VERSION ""

NS_ :

BS_:

BU_: DBG VCU
VAL_TABLE_ WhySpeedLimit 30014 "DCDC Temp fault" 30013 "Drive clutch stuck" 30012 "PTO clutch stuck" 30011 "Transmission pressure sensor OOR" 30010 "Clutch Brake interlock" 30009 "Hydraulic over temp" 30008 "Steering issue" 30007 "Brake Pedal Position Sensor OOR" 30006 "Right Brake Position Sensor OOR" 30005 "Left Brake Position Sensor OOR" 30004 "Right wheel speed sensor OOR" 30003 "Left wheel speed sensor OOR" 30002 "Brakes requested" 30001 "Zero speed limit from the roof" 30000 "Good" ;
VAL_TABLE_ Steering_Faults 20826 "Right Pressure Out of Range" 20825 "Left Pressure Out of Range" 20824 "TFD Loss of Comm" 20823 "Sensor Not Calibrated" 20822 "Valve Stuck Open towards Right" 20821 "Ecotron Loss of Comm" 20820 "LH Red Sensor Out of Calibration" 20819 "RH Red sensor Out of Calibration" 20818 "Steering Loss of Comm" 20817 "Left Red Sensor Open Cicruit" 20816 "Rght Snsor Failed Crosscheck" 20815 "Right Redundant Sensor OC" 20814 "RH Red Sensor Short to Pwr" 20813 "Valve Stuck Closed" 20812 "Left Sensor Failed Crosscheck" 20811 "Left Red Sensor Short to Pwr" 20810 "Left Valve Stuck Open" 20809 "Right Line Pressure Too High" 20808 "Left Line Pressure Too High" 20807 "LH Primary Out of Calibration" 20806 "RH Primary Out of Calibration" 20805 "Primary Primary Xcheck Error" 20804 "LH Sensor Primary Short to pwr" 20803 "RH Sensor Primary short to pwr" 20802 "Left Sensor Primary OC" 20801 "Right Sensor Primary OC" 20800 "No Faults" 0 "No Faults" ;
VAL_TABLE_ VT_Gearbox_Subsystem 0 "No Fault" 20609 "Broken roll pin or clutch slip" 20608 "Range shifting stuck" 20607 "Gear shifting stuck" 20606 "Range sensor out of range" 20605 "Gear sensor out of range" 20604 "Shift Dial fault" 20603 "Shift Dial LoC" 20602 "Left Ecotron LoC" 20601 "Right Ecotron LoC" 20600 "No Fault" ;
VAL_TABLE_ ChargerPP 2 "Charger Connected" 1 "Charger Detected" 0 "Not connected" ;
VAL_TABLE_ Charger_PP 2 "Charger Connected" 1 "Charger Detected" 0 "Charger Not Connected" ;
VAL_TABLE_ General_Flt 20066 "Front Aux Power Flt" 20065 "Front PCB Flt" 20064 "Rear Aux Power Flt" 20063 "Rear PCB Flt" 20062 "Rear Light Flt" 20061 "Front Light Flt" 20060 "Spare Power Flt" 20059 "Left Light Flt" 20058 "Right Light Flt" 20057 "AV Power Flt" 20056 "Wifi power Flt" 20055 "Front Fans Flt" 20054 "PE fan Flt" 20053 "Oil Fan Flt" 20052 "PE Pump Flt" 20051 "12V outlet Flt" 20050 "Front Light Strip Flt" 20049 "Ix_bed Ch7 Flt" 20048 "Charger Relay Flt" 20047 "Trailer Brake Light Flt" 20046 "Ix_bed Ch4 Flt" 20045 "High beam Flt" 20044 "Low Beam Flt" 20043 "Running Light Flt" 20042 "Relay14_ACDB Power" 20041 "Relay13_Front Sensor" 20040 "Relay12_BattPower" 20039 "Relay11_HV Ign" 20038 "Relay10_TFD Ign" 20037 "Relay9_TTC580 Ign" 20036 "Relay8_TTC580 Power" 20035 "Relay7_ Pump Ign" 20034 "Relay6_HMI Ign" 20033 "Relay5_EHI Ign" 20032 "Relay4_Right Turn Signal" 20031 "Relay3_mRFRM Ign" 20030 "Relay2_Left Turn Signal " 20029 "Relay1_Autonomy Cams" 20028 "Fuse28_TTC580 Power" 20027 "Fuse27_Ecotrons2" 20026 "Fuse26_ACDB Power" 20025 "Fuse25_Front Sensor" 20024 "Fuse24_BMS power" 20023 "Fuse23_HV Ign" 20022 "Fuse22_mRFRFM Power" 20021 "Fuse21_ Ecotrons1" 20020 "Fuse20_Vmax Power" 20019 "Fuse19_ OTA TTC580" 20018 "Fuse18_TFD" 20017 "Fuse17_TTC580 Ubatt" 20016 "Fuse16_TractorPump Ign" 20015 "Fuse15_ TTC580 Ign" 20014 "Fuse14_SevconPower2" 20013 "Fuse13_SevconPower1" 20012 "Fuse12_ SIMPL Power" 20011 "Fuse11_MTA Power" 20010 "Fuse10_Steering Valve" 20009 "Fuse9_ HMI Power" 20008 "Fuse8_Right Turn Signal" 20007 "Fuse7_Left Turn Signal" 20006 "Fuse6_empty" 20005 "Fuse5_ISOBus Power" 20004 "Fuse4_EstopCharger" 20003 "Fuse3_empty" 20002 "Fuse2_VmaxHVIL" 20001 "Fuse1_Autonomy Cams" 0 "No Fault" ;
VAL_TABLE_ Battery_Subsystem 24 "HV battery Low" 23 "12 Battery Low" 22 "Tractor HVIL" 21 "BMS HVIL" 20 "Lower BMS Severe Fault" 19 "Lower String High CellV" 18 "Lower String Over Voltage" 17 "Lower String Low CellV" 16 "Lower String Low Voltage" 15 "Upper BMS Severe Fault" 14 "Upper String High CellV" 13 "Upper String Over Voltage" 12 "Upper String Low CellV" 11 "Upper String low Voltage" 10 "Pack imbl_ Upper Active" 9 "Pack imbl_ Lower Active" 8 "SOC Critically Low" 7 "Low SOC" 6 "Lower String Down" 5 "Upper String Down" 4 "Voltage Imbalance" 3 "Both BMS LOC" 2 "Lower String LOC" 1 "Upper String LOC" 0 "No Fault" ;
VAL_TABLE_ Hydraulics_Flt 37 "Work Pump Pos OOR" 36 "Drive Clutch Pressure OOR" 35 "PTO Clutch Pressure OOR" 34 "Trans Acc Pressure OOR" 33 "SteerBrk Acc Pressure OOR" 32 "Suction Line Pressure OOR" 31 "Tractor Pump Pressure OOR" 30 "Work Pump Pressure OOR" 29 "Right Brake Pressure OOR" 28 "Left Brake Pressure OOR" 27 "Tractor Pump OverLoaded" 26 "RH Brake Out Of Calibration" 25 "LH Brake Out Of Calibration" 24 "RH Brake SetValve OpenCircuit" 23 "RH Brake RelValve OpenCircuit" 22 "LH Brake SetValve OpenCircuit" 21 "LH Brake RelValve OpenCircuit" 20 "RH Brake Under Engagement" 19 "LH Brake Under Engagement" 18 "RH Brake Over Engagement" 17 "LH Brake Over Engagement" 16 "PTO Engagement Interlock" 15 "PTO Clutch Valve OpenCircuit" 14 "Lube Valve OpenCircuit" 13 "Drive Clutch Valve OpenCircuit" 12 "Lube Valve Timeout" 11 "Gear mismatch clutch disengaged" 10 "Clutch Pressure Low" 9 "Aux ON/OFFvalve OpenCircuit" 8 "WorkPumpOverloaded/Air" 7 "PTO Clutch Pressure Low" 6 "TransFlowValve OpenCircuit" 5 "Trans Manifold Pressure High" 4 "Trans Manifold Pressure Low" 3 "SteerBrake Valve OpenCircuit" 2 "SteerBrake Acc Press High" 1 "SteerBrake Acc Press Low" 0 "No Fault" ;
VAL_TABLE_ Charging_Flt 32 "Chargers Disabled" 31 "DCAC_3 Flt" 30 "DCAC_2 Flt" 29 "DCAC_1 Flt" 28 "DCDC_3 Irregular Voltage" 27 "DCDC_2 Irregular Voltage" 26 "DCDC_1 Irregular Voltage" 25 "Chg_3 OBC Flt" 24 "Chg_2 OBC Flt" 23 "Chg_1 OBC Flt" 22 "DCDC_3 OverTemp" 21 "DCDC_2 OverTemp" 20 "DCDC_1 OverTemp" 19 "Chg_3 OverTemp " 18 "Chg_2 OverTemp" 17 "Chg_1 OverTemp" 16 "DCDC_3 Flt" 15 "DCDC_2 Flt" 14 "DCDC_1 Flt" 13 "ACDB eFuse8 OverCurrent" 12 "ACDB eFuse6 OverCurrent" 11 "ACDB eFuse3 OverCurrent" 10 "ACDB eFuse1 OverCurrent" 9 "ACDB Conv. Error" 8 "ACDB SIMPL Error" 7 "ACDB EVSE Error" 6 "ACDB 3Ph Error" 5 "ACDB 1Ph Error" 4 "ACDB OverTemp" 3 "ACDB disabled" 2 "Charger Improper Connection" 1 "Charger LOC" 0 "No Fault" ;
VAL_TABLE_ Thermal_Flt 5 "Hyd Over Temp Protection" 4 "Hyd Over Temp Warning" 3 "Cooling Pump Disconnected" 2 "Air in cooling system" 1 "Cooling Pump OverCurrent" 0 "No Fault" ;
VAL_TABLE_ Traction_Flt 23 "Inverter LOC" 22 "Regen Limited" 21 "Regen Disabled" 20 "Clutch Interlock" 19 "Motor Over loaded" 18 "bStart Check Fail" 17 "Disengage by Accel." 16 "Min Cell Voltage Low" 15 "DC Link Voltage Low" 14 "Pack Voltage Low" 13 "Speed Input Error" 12 "Motor Torque Limit" 11 "Insufficient Torque Applied" 10 "Hydraulic Oil Over Temp" 9 "Inverter Over Temperature" 8 "Inverter Fault OFF" 7 "Control Word Check Error" 6 "Hand Throttle Error" 5 "Hand Throttle Ch2 OOR" 4 "Hand Throttle Ch1 OOR" 3 "Foot Throttle Error" 2 "Foot Throttle Ch2 OOR" 1 "Foot Throttle Ch1 OOR" 0 "No Fault" ;
VAL_TABLE_ Shift_Position_Error 0 "Not In Any Target" ;
VAL_TABLE_ STATE_CONTACTORS 2 "CLOSED" 1 "PRECHARGE IN PROCESS" 0 "OPEN" ;
VAL_TABLE_ OVERRIDE_BRAKE_LIGHT 3 "FUNCTION NOT AVAILABLE" 2 "ENABLE OVERRIDE TO ON" 1 "ENABLE OVERRIDE TO OFF" 0 "DISABLE OVERRIDE" ;
VAL_TABLE_ STATE_SHIFT 2 "REVERSE" 1 "FORWARD" 0 "NEUTRAL/PARK" ;
VAL_TABLE_ STATE_GEAR_POSITION 12 "POSITION 12" 11 "POSITION 11" 10 "POSITION 10" 9 "POSITION 09" 8 "POSITION 08" 7 "POSITION 07" 6 "POSITION 06" 5 "POSITION 05" 4 "POSITION 04" 3 "POSITION 03" 2 "POSITION 02" 1 "POSITION 01" 0 "NEUTRAL" ;
VAL_TABLE_ STATE_HEAD_LIGHT 3 "HIGH_BEAM" 2 "LOW_BEAM" 1 "RUNNING_LIGHT" 0 "OFF" ;
VAL_TABLE_ STATE_TURN_SIGNAL 3 "HAZARD" 2 "RIGHT" 1 "LEFT" 0 "OFF" ;
VAL_TABLE_ State 7 "Reserved" 6 "Reserved" 5 "Float" 4 "Turn Off" 3 "Consider Turn Off" 2 "Tracking Active" 1 "Tracking Desired" 0 "Initialization" ;

BO_ 3221225472 VECTOR__INDEPENDENT_SIG_MSG: 0 Vector__XXX
 SG_ VehicleSpeed_kmoh : 0|8@1- (1,0) [0|0] "" Vector__XXX
 SG_ VCU_CtrlTrePt_EstimateMassFromFo : 0|12@1- (1,0) [-2048|2047] "kg" Vector__XXX
 SG_ VCU_CtrlTrePt_EndAHeight_Right : 0|8@1+ (0.01,0) [0|2.55] "m" Vector__XXX
 SG_ VCU_CtrlTrePt_EndAHeight_Left : 0|8@1+ (0.01,0) [0|2.55] "m" Vector__XXX
 SG_ VCU_CtrlTrePt_CylinderPosition_R : 0|8@1+ (0.4,0) [0|102] "%" Vector__XXX
 SG_ VCU_CtrlTrePt_CylinderPosition_L : 0|8@1+ (0.4,0) [0|102] "%" Vector__XXX
 SG_ VCU_CtrlTrePt_State_Right : 0|3@1+ (1,0) [0|7] "" Vector__XXX
 SG_ VCU_CtrlTrePt_State_Left : 0|3@1+ (1,0) [0|7] "" Vector__XXX
 SG_ VCU_CtrlTrePt_EnPressurePID_Righ : 0|1@1+ (1,0) [0|1] "" Vector__XXX
 SG_ VCU_CtrlTrePt_EnPressurePID_Left : 0|1@1+ (1,0) [0|1] "" Vector__XXX
 SG_ VCU_CtrlTrePt_Force_Right_OnGrou : 0|12@1- (0.01,0) [-20.48|20.47] "kN" Vector__XXX
 SG_ VCU_CtrlTrePt_Force_Right_Error : 0|14@1- (0.01,0) [-81.92|81.91] "kN" Vector__XXX
 SG_ VCU_CtrlTrePt_Force_Right_EquivM : 0|12@1- (0.01,0) [-20.48|20.47] "kN" Vector__XXX
 SG_ VCU_CtrlTrePt_Force_Right_Actual : 0|14@1- (0.01,0) [-81.92|81.91] "kN" Vector__XXX
 SG_ VCU_CtrlTrePt_Force_Right_Acc : 0|12@1- (0.01,0) [-20.48|20.47] "kN" Vector__XXX
 SG_ VCU_CtrlTrePt_Force_Left_OnGroun : 0|12@1- (0.01,0) [-20.48|20.47] "kN" Vector__XXX
 SG_ VCU_CtrlTrePt_Force_Left_Error : 0|14@1- (0.01,0) [-81.92|81.91] "kN" Vector__XXX
 SG_ VCU_CtrlTrePt_Force_Left_Actual : 0|14@1- (0.01,0) [-81.92|81.91] "kN" Vector__XXX
 SG_ VCU_CtrlTrePt_Force_Left_Acc : 0|12@1- (0.01,0) [-20.48|20.47] "kN" Vector__XXX
 SG_ VCU_CtrlTrePt_Force_Left_EquivMa : 0|12@1- (0.01,0) [-20.48|20.47] "kN" Vector__XXX
 SG_ power_hydraulic : 0|16@1+ (1,0) [0|65535] "W" Vector__XXX
 SG_ power_DCDC : 0|12@1+ (1,0) [0|4095] "W" Vector__XXX
 SG_ three_point_depth_position_senso : 0|14@1+ (1,0) [0|16383] "mV" Vector__XXX
 SG_ do3_right_three_point_up_valve_d : 0|16@1+ (0.00152590218966964,0) [0|100] "%" Vector__XXX
 SG_ do3_right_three_point_down_valve : 0|16@1+ (0.00152590218966964,0) [0|100] "%" Vector__XXX
 SG_ three_point_depth_position__0000 : 0|14@1+ (1,0) [0|16383] "mV" Vector__XXX
 SG_ do3_left_three_point_down_valve_ : 0|16@1+ (0.00152590218966964,0) [0|100] "%" Vector__XXX
 SG_ do3_left_three_point_up_valve_du : 0|16@1+ (0.00152590218966964,0) [0|100] "%" Vector__XXX
 SG_ range_control_execute : 0|1@1+ (1,0) [0|1] "" Vector__XXX
 SG_ range_control_done : 0|1@1+ (1,0) [0|1] "" Vector__XXX
 SG_ range_control_busy : 0|1@1+ (1,0) [0|1] "" Vector__XXX
 SG_ range_control_abort : 0|1@1+ (1,0) [0|1] "" Vector__XXX
 SG_ range_target_position_voltage : 0|13@1+ (1,0) [0|8191] "mV" Vector__XXX
 SG_ range_target_position_logical : 0|4@1+ (1,0) [0|15] "" Vector__XXX
 SG_ range_feedback_position_voltage : 0|13@1+ (1,0) [0|8191] "mV" Vector__XXX
 SG_ range_feedback_position_logical : 0|4@1+ (1,0) [0|15] "" Vector__XXX
 SG_ gear_control_abort : 0|1@1+ (1,0) [0|1] "" Vector__XXX
 SG_ gear_control_busy : 0|1@1+ (1,0) [0|1] "" Vector__XXX
 SG_ gear_control_done : 0|1@1+ (1,0) [0|1] "" Vector__XXX
 SG_ gear_control_execute : 0|1@1+ (1,0) [0|1] "" Vector__XXX
 SG_ gear_feedback_position_logical : 0|4@1+ (1,0) [0|15] "" Vector__XXX
 SG_ gear_target_position_logical : 0|4@1+ (1,0) [0|15] "" Vector__XXX
 SG_ gear_feedback_position_voltage : 0|13@1+ (1,0) [0|8191] "mV" Vector__XXX
 SG_ gear_target_position_voltage : 0|13@1+ (1,0) [0|8191] "mV" Vector__XXX
 SG_ right_wheel_speed_sensor_motion_ : 0|1@1+ (1,0) [0|1] "" Vector__XXX
 SG_ right_wheel_speed_sensor_calcula : 0|12@1+ (0.001,0) [0|4.095] "" Vector__XXX
 SG_ right_wheel_speed_sensor_pulse_w : 0|24@1+ (1,0) [0|16777215] "us" Vector__XXX
 SG_ right_wheel_speed_sensor_freq_ra : 0|16@1+ (1,0) [0|65535] "mHz" Vector__XXX
 SG_ right_wheel_speed_sensor_error : 0|8@1+ (1,0) [0|255] "" Vector__XXX
 SG_ RightBrkSpeed_Pcnt : 0|8@1+ (1,0) [0|255] "%" Vector__XXX
 SG_ LeftBrkSpeed_Pcnt : 0|8@1+ (1,0) [0|255] "%" Vector__XXX
 SG_ right_wheel_speed_raw : 0|8@1+ (1,0) [0|255] "rpm" Vector__XXX
 SG_ left_wheel_speed_raw : 0|8@1+ (1,0) [0|65535] "rpm" Vector__XXX
 SG_ right_whee_speed : 0|8@1+ (1,0) [0|65535] "rpm" Vector__XXX
 SG_ left_whee_speed : 0|8@1+ (1,0) [0|65535] "rpm" Vector__XXX
 SG_ left_wheel_speed_sensor_motion_d : 0|1@1+ (1,0) [0|1] "" Vector__XXX
 SG_ left_wheel_speed_sensor_calculat : 0|12@1+ (0.001,0) [0|4.095] "" Vector__XXX
 SG_ left_wheel_speed_sensor_error : 0|8@1+ (1,0) [0|255] "" Vector__XXX
 SG_ left_wheel_speed_sensor_pulse_wi : 0|24@1+ (1,0) [0|16777215] "us" Vector__XXX
 SG_ left_wheel_speed_sensor_freq_raw : 0|16@1+ (1,0) [0|65535] "mHz" Vector__XXX
 SG_ brake_pedal_switch : 0|1@1+ (1,0) [0|1] "" Vector__XXX
 SG_ three_point_depth_position__0001 : 0|12@1+ (0.025,0) [0|102.375] "%" Vector__XXX
 SG_ do3_auxiliary_b_front_a_pressure : 0|12@1+ (1,0) [0|4095] "psi" Vector__XXX
 SG_ do3_auxiliary_b_front_b_pressure : 0|12@1+ (1,0) [0|4095] "psi" Vector__XXX
 SG_ do3_auxiliary_b_rear_a_pressure : 0|12@1+ (1,0) [0|4095] "psi" Vector__XXX
 SG_ do3_auxiliary_b_rear_b_pressure : 0|12@1+ (1,0) [0|4095] "psi" Vector__XXX
 SG_ three_point_depth_position__0002 : 0|12@1+ (0.025,0) [0|102.375] "%" Vector__XXX
 SG_ do3_auxiliary_a_front_a_pressure : 0|12@1+ (1,0) [0|4095] "psi" Vector__XXX
 SG_ do3_auxiliary_a_front_b_pressure : 0|12@1+ (1,0) [0|4095] "psi" Vector__XXX
 SG_ do3_auxiliary_a_rear_a_pressure : 0|12@1+ (1,0) [0|4095] "psi" Vector__XXX
 SG_ do3_auxiliary_a_rear_b_pressure : 0|12@1+ (1,0) [0|4095] "psi" Vector__XXX
 SG_ do3_front_axle_forward_pressure : 0|12@1+ (1,0) [0|4095] "psi" Vector__XXX
 SG_ do3_front_axle_reverse_pressure : 0|12@1+ (1,0) [0|4095] "psi" Vector__XXX
 SG_ do3_implement_pressure : 0|12@1+ (1,0) [0|4095] "psi" Vector__XXX
 SG_ trans_manifold_forward_pressure : 0|12@1+ (1,0) [0|4095] "psi" Vector__XXX
 SG_ trans_manifold_reverse_pressure : 0|12@1+ (1,0) [0|4095] "psi" Vector__XXX
 SG_ trans_manifold_accumulator_press : 0|12@1+ (1,0) [0|4095] "psi" Vector__XXX
 SG_ trans_manifold_system_pressure : 0|12@1+ (1,0) [0|4095] "psi" Vector__XXX
 SG_ brake_manifold_steer_brake_accum : 0|12@1+ (1,0) [0|4095] "psi" Vector__XXX
 SG_ brake_manifold_right_hand_brake_ : 0|12@1+ (1,0) [0|4095] "psi" Vector__XXX
 SG_ brake_manifold_left_hand_brake_p : 0|12@1+ (1,0) [0|4095] "psi" Vector__XXX
 SG_ pump_power_watts : 0|16@1+ (1,0) [0|65535] "W" Vector__XXX
 SG_ pump_flow_rate_lpm : 0|16@1+ (0.001,0) [0|40] "lpm" Vector__XXX
 SG_ stock_pto_engage_valve : 0|1@1+ (1,0) [0|1] "T/F" Vector__XXX
 SG_ trans_manifold_lubrication_valve : 0|1@1+ (1,0) [0|1] "T/F" Vector__XXX
 SG_ priority_on_off_valve : 0|16@1+ (0.00152590218966964,0) [0|100] "%" Vector__XXX
 SG_ trans_manifold_reverse_valve : 0|16@1+ (0.00152590218966964,0) [0|100] "%" Vector__XXX
 SG_ trans_manifold_forward_valve : 0|16@1+ (0.00152590218966964,0) [0|100] "%" Vector__XXX
 SG_ brake_manifold_right_hand_b_0000 : 0|16@1+ (0.00152590218966964,0) [0|100] "%" Vector__XXX
 SG_ brake_manifold_left_hand_brake_s : 0|16@1+ (0.00152590218966964,0) [0|100] "%" Vector__XXX
 SG_ FWD_RPM : 0|16@1- (0.1,0) [-3276.8|3276.7] "" Vector__XXX
 SG_ energy_hydraulic : 0|12@1+ (3,0) [0|12285] "Wh" Vector__XXX
 SG_ energy_DCDC : 0|12@1+ (3,0) [0|12285] "Wh" Vector__XXX
 SG_ energy_battery : 0|16@1- (4,0) [-131072|131068] "Wh" Vector__XXX
 SG_ energy_mechanical : 0|16@1- (4,0) [-131072|131068] "Wh" Vector__XXX
 SG_ FWDbraking_SM_diag : 0|5@1- (0.5,0) [-8|7.5] "" Vector__XXX
 SG_ ShiftState : 0|5@1+ (1,0) [0|31] "" Vector__XXX
 SG_ SM1_3Pt_Toplink_Angle_mV : 0|13@1+ (1,0) [0|8191] "" Vector__XXX
 SG_ SM1_3Pt_Toplink_Angle_pct : 0|6@1- (1.6,0) [-51.2|49.6] "" Vector__XXX
 SG_ SM1_3Pt_RH_Angle_pct : 0|6@1+ (1.6,0) [0|0] "" Vector__XXX
 SG_ SM1_3Pt_RH_Angle_mV : 0|13@1+ (1,0) [0|8191] "" Vector__XXX
 SG_ SM1_3Pt_LH_Angle_pct : 0|6@1+ (1.6,0) [0|100.8] "" Vector__XXX
 SG_ SM1_3Pt_LH_Angle_mV : 0|13@1+ (1,0) [0|8191] "" Vector__XXX

BO_ 1901 VCU_FaultCodes: 8 Vector__XXX
 SG_ whyDisabled m3 : 24|8@1+ (1,30300) [30300|30555] "" Vector__XXX
 SG_ WhySpeedLimit m1 : 56|8@1+ (1,30000) [30000|30255] "" Vector__XXX
 SG_ Accessories_Subsystem m3 : 8|16@1+ (1,0) [0|255] "" Vector__XXX
 SG_ FirstFault m0 : 56|8@1+ (1,0) [0|255] "" Vector__XXX
 SG_ IMPL_Subsystem m2 : 40|16@1+ (1,0) [0|255] "" Vector__XXX
 SG_ Steering_Subsystem m2 : 24|16@1+ (1,0) [0|255] "" Vector__XXX
 SG_ Gearbox_Subsystem m2 : 8|16@1+ (1,0) [0|255] "" Vector__XXX
 SG_ General_Subsytem m1 : 40|16@1+ (1,0) [0|255] "" Vector__XXX
 SG_ Battery_Subsystem m1 : 24|16@1+ (1,0) [0|255] "" Vector__XXX
 SG_ Hydraulic_Subsystem m1 : 8|16@1+ (1,0) [0|65535] "" Vector__XXX
 SG_ Charging_Subsystem m0 : 40|16@1+ (1,0) [0|32767] "" Vector__XXX
 SG_ Fault_Code_mux M : 0|8@1+ (1,0) [0|255] "" Vector__XXX
 SG_ Thermal_Subsystem m0 : 24|16@1+ (1,0) [0|65535] "" Vector__XXX
 SG_ Traction_Subsystem m0 : 8|16@1+ (1,0) [0|65535] "" Vector__XXX

BO_ 1300 VCU_Geartrain: 8 Vector__XXX
 SG_ SunGearRPM m4 : 34|16@1- (0.05,0) [-1638.4|1638.35] "" Vector__XXX
 SG_ ShiftFeedback m1 : 52|4@1+ (1,0) [0|15] "" Vector__XXX
 SG_ Charger_PP m2 : 54|2@1+ (1,0) [0|3] "" Vector__XXX
 SG_ Power_Motor_kW_Output m1 : 8|8@1- (1,0) [-128|127] "kW" Vector__XXX
 SG_ Power_Wheel_kW m2 : 0|10@1- (0.1,0) [-51.2|51.1] "kW" Vector__XXX
 SG_ Power_PumpMech_kW m2 : 56|4@1+ (0.2,0) [0|3] "kW" Vector__XXX
 SG_ Power_PumpHyd_kW m2 : 10|8@1+ (0.1,0) [0|25.5] "kW" Vector__XXX
 SG_ Power_PTO_kW m2 : 26|10@1- (0.1,0) [-51.2|51.1] "kW" Vector__XXX
 SG_ Power_Motor_kW_input m2 : 36|8@1- (1,0) [-128|127] "kW" Vector__XXX
 SG_ Power_Drivetrain_kW m2 : 44|10@1- (0.1,20) [-31.2|71.1] "kW" Vector__XXX
 SG_ Power_Battery_kW m2 : 18|8@1- (1,0) [-128|127] "kW" Vector__XXX
 SG_ kWh_per_min m3 : 0|5@1+ (1,0) [0|31] "" Vector__XXX
 SG_ SOC_Rate m3 : 5|4@1+ (1,0) [0|15] "" Vector__XXX
 SG_ TTE m3 : 9|10@1+ (1,0) [0|1023] "" Vector__XXX
 SG_ GoodStringState m3 : 19|3@1+ (1,0) [0|7] "" Vector__XXX
 SG_ Update m3 : 22|1@1+ (1,0) [0|1] "" Vector__XXX
 SG_ T_Init m4 : 0|10@1+ (1,0) [0|1023] "" Vector__XXX
 SG_ SOC_Init m4 : 10|7@1+ (1,0) [0|127] "" Vector__XXX
 SG_ Prev_T m4 : 17|10@1+ (1,0) [0|1023] "" Vector__XXX
 SG_ Prev_SOC m4 : 27|7@1+ (1,0) [0|127] "" Vector__XXX
 SG_ Plug m3 : 23|1@1+ (1,0) [0|1] "" Vector__XXX
 SG_ Clock m3 : 24|10@1+ (1,0) [0|1023] "" Vector__XXX
 SG_ Current_SOC m3 : 34|7@1+ (1,0) [0|127] "" Vector__XXX
 SG_ u8_State m3 : 41|4@1+ (1,0) [0|15] "" Vector__XXX
 SG_ FWDbraking_SM_diag m3 : 50|5@1- (0.5,0) [-8|7.5] "" Vector__XXX
 SG_ FWD_slip_pcnt m1 : 0|8@1- (1,0) [-128|127] "%" Vector__XXX
 SG_ FWD_Target_RPM m1 : 32|16@1- (0.1,0) [-3276.8|3276.7] "" Vector__XXX
 SG_ FWD_RPM_KF m1 : 16|16@1- (0.1,0) [-3276.8|3276.7] "" Vector__XXX
 SG_ Geartrain_MUX M : 60|4@1+ (1,0) [0|15] "" Vector__XXX
 SG_ ShiftState m3 : 45|5@1+ (1,0) [0|31] "" Vector__XXX
 SG_ TargetRightwheelSpeed m0 : 52|8@1+ (1,0) [0|255] "RPM" Vector__XXX
 SG_ TargetRightBrake_Pcnt m0 : 45|7@1+ (1,0) [0|127] "" Vector__XXX
 SG_ TargetLeftwheelSpeed m0 : 37|8@1+ (1,0) [0|255] "RPM" Vector__XXX
 SG_ TargetLeftBrake_Pcnt m0 : 30|7@1+ (1,0) [0|127] "" Vector__XXX
 SG_ RightBrake_Pcnt m0 : 23|7@1+ (1,0) [0|127] "" Vector__XXX
 SG_ LeftBrake_Pcnt m0 : 16|7@1+ (1,0) [0|127] "" Vector__XXX
 SG_ RangeTargetPos m0 : 12|4@1+ (1,0) [0|15] "" Vector__XXX
 SG_ RangeFBKPos m0 : 8|4@1+ (1,0) [0|15] "" Vector__XXX
 SG_ GearTargetPos m0 : 4|4@1+ (1,0) [0|15] "" Vector__XXX
 SG_ GearFBKPos m0 : 0|4@1+ (1,0) [0|15] "" Vector__XXX

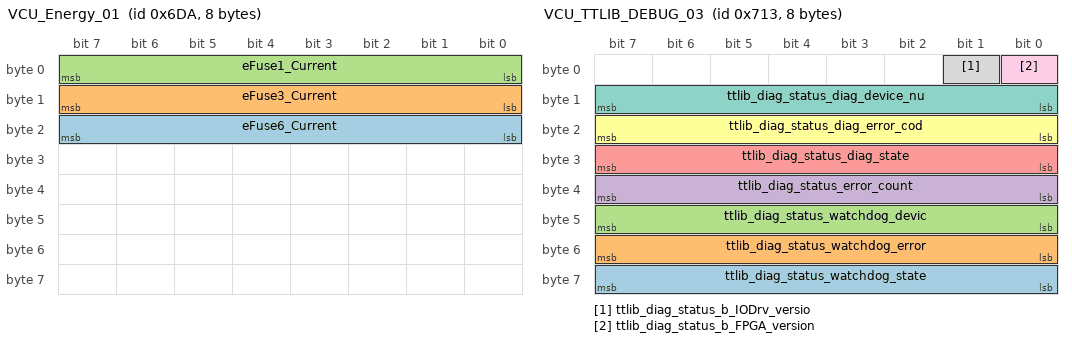
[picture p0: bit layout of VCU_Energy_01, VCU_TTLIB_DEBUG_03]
BO_ 1754 VCU_Energy_01: 8 VCU
 SG_ eFuse6_Current : 16|8@1+ (0.2,0) [0|51] "A" Vector__XXX
 SG_ eFuse3_Current : 8|8@1+ (0.2,0) [0|51] "A" Vector__XXX
 SG_ eFuse1_Current : 0|8@1+ (0.2,0) [0|51] "" Vector__XXX

BO_ 1811 VCU_TTLIB_DEBUG_03: 8 VCU
 SG_ ttlib_diag_status_watchdog_state : 56|8@1+ (1,0) [0|255] "" Vector__XXX
 SG_ ttlib_diag_status_watchdog_error : 48|8@1+ (1,0) [0|255] "" Vector__XXX
 SG_ ttlib_diag_status_watchdog_devic : 40|8@1+ (1,0) [0|255] "" Vector__XXX
 SG_ ttlib_diag_status_error_count : 32|8@1+ (1,0) [0|255] "" Vector__XXX
 SG_ ttlib_diag_status_diag_state : 24|8@1+ (1,0) [0|255] "" Vector__XXX
 SG_ ttlib_diag_status_diag_error_cod : 16|8@1+ (1,0) [0|255] "" Vector__XXX
 SG_ ttlib_diag_status_diag_device_nu : 8|8@1+ (1,0) [0|255] "" Vector__XXX
 SG_ ttlib_diag_status_b_IODrv_versio : 1|1@1+ (1,0) [0|1] "" Vector__XXX
 SG_ ttlib_diag_status_b_FPGA_version : 0|1@1+ (1,0) [0|1] "" Vector__XXX

BO_ 1810 VCU_TTLIB_DEBUG_02: 8 VCU
 SG_ ttlib_diag_status_watchdog_fault : 32|32@1+ (1,0) [0|4294967295] "" Vector__XXX
 SG_ ttlib_diag_status_diag_faulty_va : 0|32@1+ (1,0) [0|4294967295] "" Vector__XXX

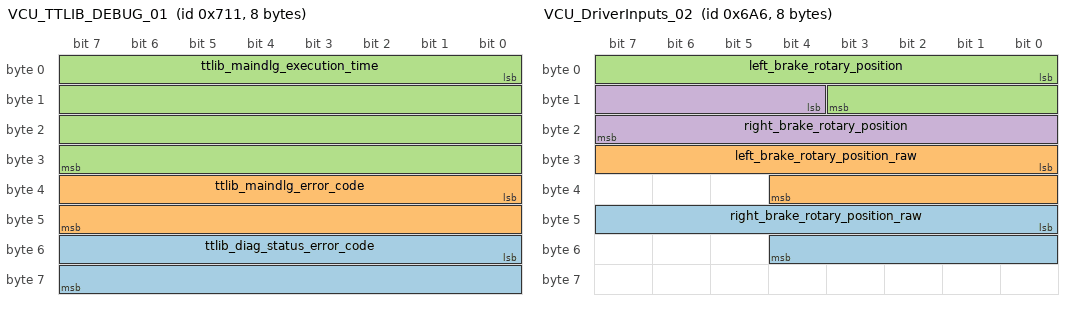
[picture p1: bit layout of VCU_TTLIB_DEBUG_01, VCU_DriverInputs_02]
BO_ 1809 VCU_TTLIB_DEBUG_01: 8 VCU
 SG_ ttlib_diag_status_error_code : 48|16@1+ (1,0) [0|65535] "" Vector__XXX
 SG_ ttlib_maindlg_error_code : 32|16@1+ (1,0) [0|65535] "" Vector__XXX
 SG_ ttlib_maindlg_execution_time : 0|32@1+ (1,0) [0|4294967295] "us" Vector__XXX

BO_ 1702 VCU_DriverInputs_02: 8 VCU
 SG_ right_brake_rotary_position_raw : 40|13@1+ (1,0) [0|8191] "mV" Vector__XXX
 SG_ left_brake_rotary_position_raw : 24|13@1+ (1,0) [0|8191] "mV" Vector__XXX
 SG_ left_brake_rotary_position : 0|12@1+ (0.025,0) [0|102.375] "%" Vector__XXX
 SG_ right_brake_rotary_position : 12|12@1+ (0.025,0) [0|102.375] "%" Vector__XXX

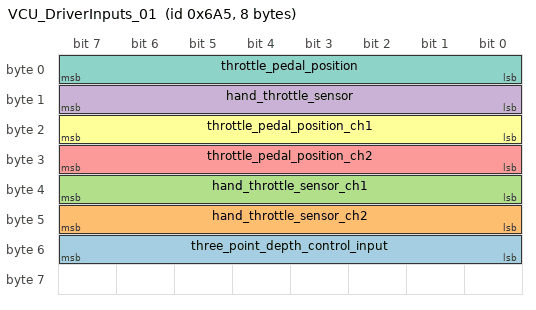
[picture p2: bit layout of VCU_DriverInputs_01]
BO_ 1701 VCU_DriverInputs_01: 8 VCU
 SG_ three_point_depth_control_input : 48|8@1+ (0.5,0) [0|127.5] "%" Vector__XXX
 SG_ hand_throttle_sensor_ch2 : 40|8@1+ (0.5,0) [0|127.5] "%" Vector__XXX
 SG_ hand_throttle_sensor_ch1 : 32|8@1+ (0.5,0) [0|127.5] "%" Vector__XXX
 SG_ hand_throttle_sensor : 8|8@1+ (0.5,0) [0|127.5] "%" Vector__XXX
 SG_ throttle_pedal_position_ch2 : 24|8@1+ (0.5,0) [0|127.5] "%" Vector__XXX
 SG_ throttle_pedal_position_ch1 : 16|8@1+ (0.5,0) [0|127.5] "%" Vector__XXX
 SG_ throttle_pedal_position : 0|8@1+ (0.5,0) [0|127.5] "%" Vector__XXX

BO_ 1697 VCU_HydraulicPressure: 8 VCU
 SG_ WorkPumpTargetPressure_bar m3 : 56|8@1+ (1,0) [0|255] "bar" Vector__XXX
 SG_ Steering_Right_Pressure_bar m3 : 40|8@1+ (1,0) [0|255] "bar" Vector__XXX
 SG_ Steering_Left_Pressure_bar m3 : 48|8@1+ (1,0) [0|255] "bar" Vector__XXX
 SG_ ThreePoint_Aux6BPress_bar m3 : 32|8@1+ (1,0) [0|255] "" Vector__XXX
 SG_ ThreePoint_Aux6APress_bar m3 : 24|8@1+ (1,0) [0|255] "" Vector__XXX
 SG_ ThreePoint_Aux2BPress_bar m3 : 16|8@1+ (1,0) [0|255] "" Vector__XXX
 SG_ ThreePoint_Aux2APress_bar m3 : 8|8@1+ (1,0) [0|255] "" Vector__XXX
 SG_ SGBorImplOnOffPress_bar m2 : 56|8@1+ (1,0) [0|255] "" Vector__XXX
 SG_ Pump_TargetLPM m2 : 40|8@1+ (0.34,0) [0|86.7] "" Vector__XXX
 SG_ Pump_LPM m2 : 48|8@1+ (0.34,0) [0|86.7] "" Vector__XXX
 SG_ FWD_Press_bar m2 : 32|8@1+ (1,0) [0|255] "" Vector__XXX
 SG_ OilRadiator_OutletPress m2 : 16|8@1+ (0.03,0) [0|7.65] "" Vector__XXX
 SG_ OilRadiator_InletPress m2 : 24|8@1+ (0.03,0) [0|7.65] "" Vector__XXX
 SG_ SuctionLinePress m2 : 8|8@1+ (0.01,0) [0|2.55] "" Vector__XXX
 SG_ TopLink_Extend_Press_bar m1 : 56|8@1+ (1,0) [0|255] "" Vector__XXX
 SG_ TopLink_Retract_Press_bar m1 : 48|8@1+ (1,0) [0|255] "" Vector__XXX
 SG_ ThreePoint_RightRaisePress_bar m1 : 8|8@1+ (1,0) [0|255] "" Vector__XXX
 SG_ ThreePoint_RightLowerPress_bar m1 : 16|8@1+ (1,0) [0|255] "" Vector__XXX
 SG_ ThreePoint_LeftRaisePress_bar m1 : 24|8@1+ (1,0) [0|255] "" Vector__XXX
 SG_ ThreePoint_LeftLowerPress_bar m1 : 32|8@1+ (1,0) [0|255] "" Vector__XXX
 SG_ SteerBrakeAccumulatorPress m1 : 40|8@1+ (1,0) [0|255] "bar" Vector__XXX
 SG_ HydraulicPressure_Mux M : 0|8@1+ (1,0) [0|255] "" Vector__XXX
 SG_ PTOClutchPressure_bar m0 : 56|8@1+ (1,0) [0|255] "bar" Vector__XXX
 SG_ DriveClutchPressure_bar m0 : 48|8@1+ (1,0) [0|255] "bar" Vector__XXX
 SG_ WorkPumpPressure_bar m0 : 40|8@1+ (1,0) [0|255] "bar" Vector__XXX
 SG_ TractorPumpPressure_bar m0 : 32|8@1+ (1,0) [0|255] "bar" Vector__XXX
 SG_ RightBrakeAccumulatorPress m0 : 24|8@1+ (1,0) [0|255] "bar" Vector__XXX
 SG_ LeftBrakeAccumulatorPress m0 : 16|8@1+ (1,0) [0|255] "bar" Vector__XXX
 SG_ TransManifoldPress_bar m0 : 8|8@1+ (1,0) [0|255] "" Vector__XXX

BO_ 1585 VCU_HydraulicControl: 8 VCU
 SG_ PumpLpm6_BrakeLube m3 : 3|5@1+ (1,0) [0|31] "lpm" Vector__XXX
 SG_ SGBorAuxBypassValve_DO m3 : 59|1@1+ (1,0) [0|1] "" Vector__XXX
 SG_ FWD_Quadrant m5 : 61|3@1+ (1,0) [0|7] "" Vector__XXX
 SG_ ThreePoint_ImplRecirc_Duty m5 : 51|10@1+ (0.1,0) [0|102.3] "" Vector__XXX
 SG_ ThreePt_Lt_Raise_PrsTnk_duty m5 : 11|10@1+ (0.1,0) [0|102.3] "" Vector__XXX
 SG_ ThreePt_Lt_Raise_ON_OFF_duty m5 : 21|10@1+ (0.1,0) [0|102.3] "" Vector__XXX
 SG_ ThreePt_Lt_Lower_PrsTnk_duty m5 : 31|10@1+ (0.1,0) [0|102.3] "" Vector__XXX
 SG_ ThreePt_Lt_Lower_ON_OFF_duty m5 : 41|10@1+ (0.1,0) [0|102.3] "" Vector__XXX
 SG_ Rear_AUX_6_Float m4 : 59|1@1+ (1,0) [0|1] "" Vector__XXX
 SG_ Rear_AUX_1_Float m4 : 58|1@1+ (1,0) [0|1] "" Vector__XXX
 SG_ ThreePoint_AuxOnOff_DO m5 : 10|1@1+ (1,0) [0|1] "" Vector__XXX
 SG_ ThreePoint_RearAux6B_Duty m4 : 38|10@1+ (0.1,0) [0|102.3] "" Vector__XXX
 SG_ ThreePoint_AuxBypass_DO m5 : 9|1@1+ (1,0) [0|1] "" Vector__XXX
 SG_ ThreePoint_ConstFlow_Duty m4 : 48|10@1+ (0.1,0) [0|102.3] "" Vector__XXX
 SG_ ThreePoint_ImplRecirc_DO m5 : 8|1@1+ (1,0) [0|102.3] "" Vector__XXX
 SG_ ThreePoint_RearAux6A_Duty m4 : 28|10@1+ (0.1,0) [0|102.3] "" Vector__XXX
 SG_ ThreePoint_RearAux2B_Duty m4 : 18|10@1+ (0.1,0) [0|102.3] "" Vector__XXX
 SG_ ThreePoint_RearAux2A_Duty m4 : 8|10@1+ (0.1,0) [0|102.3] "" Vector__XXX
 SG_ Joystick_height_pcnt m3 : 51|8@1- (1,0) [-128|127] "" Vector__XXX
 SG_ Joystick_deadman m3 : 50|1@1+ (1,0) [0|1] "" Vector__XXX
 SG_ PumpLpm5_ConstFlow m3 : 38|6@1+ (1,0) [0|63] "lpm" Vector__XXX
 SG_ PumpLpm4_3Pt m3 : 44|6@1+ (1,0) [0|63] "lpm" Vector__XXX
 SG_ PumpLpm3_Cooling m2 : 58|6@1+ (1,0) [0|63] "lpm" Vector__XXX
 SG_ PumpLpm2_SteerBrk m1 : 58|6@1+ (1,0) [0|63] "lpm" Vector__XXX
 SG_ PumpLpm1_Fwd m0 : 58|6@1+ (1,0) [0|63] "lpm" Vector__XXX
 SG_ FWD_ReverseValve_Duty m3 : 28|10@1+ (0.1,0) [0|102.3] "" Vector__XXX
 SG_ FWD_ForwardValve_Duty m3 : 18|10@1+ (0.1,0) [0|102.3] "" Vector__XXX
 SG_ WorkPumpSwashPlate_Pcnt m3 : 8|10@1+ (0.1,0) [0|102.3] "%" Vector__XXX
 SG_ TopLink_Retract_Valve_Duty m2 : 8|10@1+ (0.1,0) [0|102.3] "" Vector__XXX
 SG_ TopLink_Extend_Valve_Duty m1 : 48|10@1+ (0.1,0) [0|102.3] "" Vector__XXX
 SG_ ThreePt_Rt_Raise_PrsTnk_duty m2 : 18|10@1+ (0.1,0) [0|102.3] "" Vector__XXX
 SG_ ThreePt_Rt_Raise_ON_OFF_duty m2 : 28|10@1+ (0.1,0) [0|102.3] "" Vector__XXX
 SG_ ThreePt_Rt_Lower_ON_OFF_duty m2 : 38|10@1+ (0.1,0) [0|102.3] "" Vector__XXX
 SG_ ThreePt_Rt_Lower_PrsTnk_duty m2 : 48|10@1+ (0.1,0) [0|102.3] "" Vector__XXX
 SG_ PTO_ClutchValve m1 : 38|10@1+ (0.1,0) [0|102.3] "%" Vector__XXX
 SG_ WorkPumpDutyCycle m0 : 48|10@1+ (0.1,0) [0|102.3] "%" Vector__XXX
 SG_ LubricationValve m1 : 28|10@1+ (0.1,0) [0|102.3] "%" Vector__XXX
 SG_ HydraulicControl_Mux M : 0|3@1+ (1,0) [0|7] "" Vector__XXX
 SG_ TransFlowControlValve m1 : 18|10@1+ (0.1,0) [0|102.3] "%" Vector__XXX
 SG_ DriveClutch_Valve m1 : 8|10@1+ (0.1,0) [0|102.3] "%" Vector__XXX
 SG_ RightBrakeSetValve m0 : 38|10@1+ (0.1,0) [0|102.3] "%" Vector__XXX
 SG_ RightBrakeReleaseValve m0 : 28|10@1+ (0.1,0) [0|102.3] "%" Vector__XXX
 SG_ LeftBrakeSetValve m0 : 18|10@1+ (0.1,0) [0|102.3] "%" Vector__XXX
 SG_ LeftBrakeReleaseValve m0 : 8|10@1+ (0.1,0) [0|102.3] "%" Vector__XXX

CM_ BO_ 3221225472 "This is a message for not used signals, created by Vector CANdb++ DBC OLE DB Provider.";
BA_DEF_  "version" STRING ;
BA_DEF_ BO_  "GenMsgSendType" ENUM  "Cyclic","NotUsed","NotUsed","NotUsed","NotUsed","NotUsed","NotUsed","IfActive","NoMsgSendType","NotUsed","vector_leerstring";
BA_DEF_ BO_  "GenMsgCycleTime" INT 0 50000;
BA_DEF_ SG_  "SystemSignalLongSymbol" STRING ;
BA_DEF_DEF_  "version" "draft_20191030";
BA_DEF_DEF_  "GenMsgSendType" "NoMsgSendType";
BA_DEF_DEF_  "GenMsgCycleTime" 0;
BA_DEF_DEF_  "SystemSignalLongSymbol" "";
BA_ "version" "";
BA_ "GenMsgSendType" BO_ 1702 0;
BA_ "GenMsgCycleTime" BO_ 1702 100;
BA_ "GenMsgSendType" BO_ 1701 0;
BA_ "GenMsgCycleTime" BO_ 1701 100;
BA_ "GenMsgSendType" BO_ 1697 0;
BA_ "GenMsgCycleTime" BO_ 1697 100;
BA_ "SystemSignalLongSymbol" SG_ 3221225472 VCU_CtrlTrePt_EstimateMassFromFo "VCU_CtrlTrePt_EstimateMassFromForce_Total";
BA_ "SystemSignalLongSymbol" SG_ 3221225472 VCU_CtrlTrePt_Force_Right_OnGrou "VCU_CtrlTrePt_Force_Right_OnGround";
BA_ "SystemSignalLongSymbol" SG_ 3221225472 VCU_CtrlTrePt_Force_Right_EquivM "VCU_CtrlTrePt_Force_Right_EquivMass";
BA_ "SystemSignalLongSymbol" SG_ 3221225472 VCU_CtrlTrePt_Force_Left_OnGroun "VCU_CtrlTrePt_Force_Left_OnGround";
BA_ "SystemSignalLongSymbol" SG_ 3221225472 VCU_CtrlTrePt_Force_Left_EquivMa "VCU_CtrlTrePt_Force_Left_EquivMass";
BA_ "SystemSignalLongSymbol" SG_ 3221225472 three_point_depth_position_senso "three_point_depth_position_sensor_right_hand_raw";
BA_ "SystemSignalLongSymbol" SG_ 3221225472 do3_right_three_point_up_valve_d "do3_right_three_point_up_valve_dutycycle";
BA_ "SystemSignalLongSymbol" SG_ 3221225472 do3_right_three_point_down_valve "do3_right_three_point_down_valve_dutycycle";
BA_ "SystemSignalLongSymbol" SG_ 3221225472 three_point_depth_position__0000 "three_point_depth_position_sensor_left_hand_raw";
BA_ "SystemSignalLongSymbol" SG_ 3221225472 do3_left_three_point_down_valve_ "do3_left_three_point_down_valve_dutycycle";
BA_ "SystemSignalLongSymbol" SG_ 3221225472 do3_left_three_point_up_valve_du "do3_left_three_point_up_valve_dutycycle";
BA_ "SystemSignalLongSymbol" SG_ 3221225472 right_wheel_speed_sensor_motion_ "right_wheel_speed_sensor_motion_detected";
BA_ "SystemSignalLongSymbol" SG_ 3221225472 right_wheel_speed_sensor_calcula "right_wheel_speed_sensor_calculated_value";
BA_ "SystemSignalLongSymbol" SG_ 3221225472 right_wheel_speed_sensor_pulse_w "right_wheel_speed_sensor_pulse_width";
BA_ "SystemSignalLongSymbol" SG_ 3221225472 right_wheel_speed_sensor_freq_ra "right_wheel_speed_sensor_freq_raw";
BA_ "SystemSignalLongSymbol" SG_ 3221225472 left_wheel_speed_sensor_motion_d "left_wheel_speed_sensor_motion_detected";
BA_ "SystemSignalLongSymbol" SG_ 3221225472 left_wheel_speed_sensor_calculat "left_wheel_speed_sensor_calculated_value";
BA_ "SystemSignalLongSymbol" SG_ 3221225472 left_wheel_speed_sensor_pulse_wi "left_wheel_speed_sensor_pulse_width";
BA_ "SystemSignalLongSymbol" SG_ 3221225472 three_point_depth_position__0001 "three_point_depth_position_sensor_right_hand";
BA_ "SystemSignalLongSymbol" SG_ 3221225472 three_point_depth_position__0002 "three_point_depth_position_sensor_left_hand";
BA_ "SystemSignalLongSymbol" SG_ 3221225472 trans_manifold_accumulator_press "trans_manifold_accumulator_pressure";
BA_ "SystemSignalLongSymbol" SG_ 3221225472 brake_manifold_steer_brake_accum "brake_manifold_steer_brake_accumulator_pressure";
BA_ "SystemSignalLongSymbol" SG_ 3221225472 brake_manifold_right_hand_brake_ "brake_manifold_right_hand_brake_pressure";
BA_ "SystemSignalLongSymbol" SG_ 3221225472 brake_manifold_left_hand_brake_p "brake_manifold_left_hand_brake_pressure";
BA_ "SystemSignalLongSymbol" SG_ 3221225472 brake_manifold_right_hand_b_0000 "brake_manifold_right_hand_brake_servo_valve";
BA_ "SystemSignalLongSymbol" SG_ 3221225472 brake_manifold_left_hand_brake_s "brake_manifold_left_hand_brake_servo_valve";
BA_ "SystemSignalLongSymbol" SG_ 1811 ttlib_diag_status_watchdog_error "ttlib_diag_status_watchdog_error_code";
BA_ "SystemSignalLongSymbol" SG_ 1811 ttlib_diag_status_watchdog_devic "ttlib_diag_status_watchdog_device_num";
BA_ "SystemSignalLongSymbol" SG_ 1811 ttlib_diag_status_diag_error_cod "ttlib_diag_status_diag_error_code";
BA_ "SystemSignalLongSymbol" SG_ 1811 ttlib_diag_status_diag_device_nu "ttlib_diag_status_diag_device_num";
BA_ "SystemSignalLongSymbol" SG_ 1811 ttlib_diag_status_b_IODrv_versio "ttlib_diag_status_b_IODrv_version_OK";
BA_ "SystemSignalLongSymbol" SG_ 1811 ttlib_diag_status_b_FPGA_version "ttlib_diag_status_b_FPGA_version_OK";
BA_ "SystemSignalLongSymbol" SG_ 1810 ttlib_diag_status_watchdog_fault "ttlib_diag_status_watchdog_faulty_value";
BA_ "SystemSignalLongSymbol" SG_ 1810 ttlib_diag_status_diag_faulty_va "ttlib_diag_status_diag_faulty_value";
VAL_ 3221225472 VCU_CtrlTrePt_State_Right 7 "Reserved" 6 "Reserved" 5 "Float" 4 "Turn Off" 3 "Consider Turn Off" 2 "Tracking Active" 1 "Tracking Desired" 0 "Initialization" ;
VAL_ 3221225472 VCU_CtrlTrePt_State_Left 7 "Reserved" 6 "Reserved" 5 "Float" 4 "Turn Off" 3 "Consider Turn Off" 2 "Tracking Active" 1 "Tracking Desired" 0 "Initialization" ;
VAL_ 3221225472 range_target_position_logical 0 "Not In Any Target" ;
VAL_ 3221225472 range_feedback_position_logical 0 "Not In Any Target" ;
VAL_ 3221225472 ShiftState 12 "Wait for clutch action" 11 "Rev match" 10 "FR shuttle-shift after regen" 9 "Regen to stop" 8 "Static gearshift abort" 7 "Rev match abort" 6 "Gear 1,3 shift 1" 5 "Gear 1,3 shift" 4 "Regular shift" 3 "Shift in motion" 2 "Stationary shift" 1 "Stationary" 0 "Undefined" ;
VAL_ 1901 WhySpeedLimit 30018 "RH Brake rel valve elec fault" 30017 "RH Brake set valve elec fault" 30016 "LH Brake rel valve elec fault" 30015 "LH Brake set valve elec fault" 30014 "DCDC Temp fault" 30013 "Drive clutch stuck" 30012 "PTO clutch stuck" 30011 "Transmission pressure sensor OOR" 30010 "Clutch Brake interlock" 30009 "Hydraulic over temp" 30008 "Steering issue" 30007 "Brake Pedal Position Sensor OOR" 30006 "Right Brake Position Sensor OOR" 30005 "Left Brake Position Sensor OOR" 30004 "Right wheel speed sensor OOR" 30003 "Left wheel speed sensor OOR" 30002 "Brakes requested" 30001 "Zero speed limit from the roof" 30000 "Good" ;
VAL_ 1901 Accessories_Subsystem 20915 "Horn open circuit" 20914 "Horn overcurrent" 20913 "Horn short circuit" 20912 "Brake light open circuit" 20911 "Brake light overcurrent" 20910 "Brake light short circuit" 20909 "High beam open circuit" 20908 "High beam overcurrent" 20907 "High beam short circuit" 20906 "Low beam open circuit" 20905 "Low beam overcurrent" 20904 "Low beam short circuit" 20903 "Front lights open circuit" 20902 "Front lights overcurrent" 20901 "Front lights short circuit" ;
VAL_ 1901 IMPL_Subsystem 20728 "Toplink position sensor OOR" 20727 "Right 3pt angle sensor OOR" 20726 "Left 3pt angle sensor OOR" 20725 "Aux bypass valve OC" 20724 "Impl recirc valve OC" 20723 "Const flow pressure sensor OC" 20722 "6B pressure sensor OC" 20721 "6A pressure sensor OC" 20720 "2B pressure sensor OC" 20719 "2A pressure sensor OC" 20718 "Toplink retract press sensor OC" 20717 "Toplink extend press sensor OC" 20716 "Right lower pressure sensor OC" 20715 "Right raise pressure sensor OC" 20714 "Left lower pressure sensor OC" 20713 "Left raise pressure sensor OC" 20712 "Const flow valve OC" 20711 "ADC 3pt limits mismatch" 20710 "Right lower valve OC" 20709 "Right raise valve OC" 20708 "Left lower valve OC" 20707 "Left raise valve OC" 20706 "Toplink retract valve OC" 20705 "Toplink extend valve OC" 20704 "2B valve OC" 20703 "2A valve OC" 20702 "6B valve OC" 20701 "6A valve OC" 20700 "No fault" 0 "No fault" ;
VAL_ 1901 Steering_Subsystem 20832 "Steering Performance Fault" 20831 "Right Valve Electrical Fault" 20830 "Left Valve Electrical Fault" 20829 "TFD Redundant Loss of Comm" 20828 "TFD Main Loss of Comm" 20827 "Spool Not Calibrated" 20826 "Right Pressure Out of Range" 20825 "Left Pressure Out of Range" 20824 "TFD Loss of Comm" 20823 "Sensor Not Calibrated" 20822 "Valve Stuck Open towards Right" 20821 "Ecotron Loss of Comm" 20820 "LH Red Sensor Out of Calibration" 20819 "RH Red sensor Out of Calibration" 20818 "Steering Loss of Comm" 20817 "Left Red Sensor Open Cicruit" 20816 "Rght Snsor Failed Crosscheck" 20815 "Right Redundant Sensor OC" 20814 "RH Red Sensor Short to Pwr" 20813 "Valve Stuck Closed" 20812 "Left Sensor Failed Crosscheck" 20811 "Left Red Sensor Short to Pwr" 20810 "Left Valve Stuck Open" 20809 "Right Line Pressure Too High" 20808 "Left Line Pressure Too High" 20807 "LH Primary Out of Calibration" 20806 "RH Primary Out of Calibration" 20805 "Primary Primary Xcheck Error" 20804 "LH Sensor Primary Short to pwr" 20803 "RH Sensor Primary short to pwr" 20802 "Left Sensor Primary OC" 20801 "Right Sensor Primary OC" 20800 "No Faults" 0 "No Faults" ;
VAL_ 1901 Gearbox_Subsystem 0 "No Fault" 20609 "Broken roll pin or clutch slip" 20608 "Range shifting stuck" 20607 "Gear shifting stuck" 20606 "Range sensor out of range" 20605 "Gear sensor out of range" 20604 "Shift Dial fault" 20603 "Shift Dial LoC" 20602 "Left Ecotron LoC" 20601 "Right Ecotron LoC" 20600 "No Fault" ;
VAL_ 1901 General_Subsytem 20069 "Dash LOC" 20068 "IX3212 bed LOC" 20067 "ADC LOC" 20000 "No Fault" 20066 "Front Aux Power Flt" 20065 "Front PCB Flt" 20064 "Rear Aux Power Flt" 20063 "Rear PCB Flt" 20062 "Rear Light Flt" 20061 "Front Light Flt" 20060 "Spare Power Flt" 20059 "Left Light Flt" 20058 "Right Light Flt" 20057 "AV Power Flt" 20056 "Wifi power Flt" 20055 "Front Fans Flt" 20054 "PE fan Flt" 20053 "Oil Fan Flt" 20052 "PE Pump Flt" 20051 "12V outlet Flt" 20050 "Front Light Strip Flt" 20049 "Ix_bed Ch7 Flt" 20048 "Charger Relay Flt" 20047 "Trailer Brake Light Flt" 20046 "Ix_bed Ch4 Flt" 20045 "High beam Flt" 20044 "Low Beam Flt" 20043 "Running Light Flt" 20042 "Relay14_ACDB Power" 20041 "Relay13_Front Sensor" 20040 "Relay12_BattPower" 20039 "Relay11_HV Ign" 20038 "Relay10_TFD Ign" 20037 "Relay9_TTC580 Ign" 20036 "Relay8_TTC580 Power" 20035 "Relay7_ Pump Ign" 20034 "Relay6_HMI Ign" 20033 "Relay5_EHI Ign" 20032 "Relay4_Right Turn Signal" 20031 "Relay3_mRFRM Ign" 20030 "Relay2_Left Turn Signal " 20029 "Relay1_Autonomy Cams" 20028 "Fuse28_TTC580 Power" 20027 "Fuse27_Ecotrons2" 20026 "Fuse26_ACDB Power" 20025 "Fuse25_Front Sensor" 20024 "Fuse24_BMS power" 20023 "Fuse23_HV Ign" 20022 "Fuse22_mRFRFM Power" 20021 "Fuse21_ Ecotrons1" 20020 "Fuse20_Vmax Power" 20019 "Fuse19_ OTA TTC580" 20018 "Fuse18_TFD" 20017 "Fuse17_TTC580 Ubatt" 20016 "Fuse16_TractorPump Ign" 20015 "Fuse15_ TTC580 Ign" 20014 "Fuse14_SevconPower2" 20013 "Fuse13_SevconPower1" 20012 "Fuse12_ SIMPL Power" 20011 "Fuse11_MTA Power" 20010 "Fuse10_Steering Valve" 20009 "Fuse9_ HMI Power" 20008 "Fuse8_Right Turn Signal" 20007 "Fuse7_Left Turn Signal" 20006 "Fuse6_empty" 20005 "Fuse5_ISOBus Power" 20004 "Fuse4_EstopCharger" 20003 "Fuse3_empty" 20002 "Fuse2_VmaxHVIL" 20001 "Fuse1_Autonomy Cams" 0 "No Fault" ;
VAL_ 1901 Battery_Subsystem 21148 "BMS1 Possible Thermal Runaway" 21248 "BMS2 Possible Thermal Runaway " 21247 "BMS2 Batt Temp Rising TooQuickly" 21246 "BMS2 Serious Overcurrent Fault" 21245 "BMS2 Precharge Relay Fault" 21244 "BMS2 Precharge Stuck Open Fault" 21243 "BMS2 Main Positive Relay Fault" 21242 "BMS2 Battery Under Voltage Lvl2" 21241 "BMS2 Battery Under Voltage Lvl1" 21240 "BMS2 Battery Over Voltage Lvl2" 21239 "BMS2 Battery Over Voltage Lvl1" 21238 "BMS2 Main Negative Relay Fault" 21237 "BMS2 Insulation Fault Lvl3" 21236 "BMS2 Insulation Fault Lvl2" 21235 "BMS2 Insulation Fault Lvl1" 21234 "BMS2 HV Mode Comm Loss" 21233 "BMS2 HVIL Fault" 21232 "BMS2 Gen Current TooHigh Lvl2" 21231 "BMS2 Gen Current TooHigh Lvl1" 21230 "BMS2 Fuse Fault" 21229 "BMS2 Discrg Current TooHigh Lvl2" 21228 "BMS2 Discrg Current TooHigh Lvl1" 21227 "BMS2 Current Sensor NoComm Relay" 21226 "BMS2 Current Sensor Fault" 21225 "BMS2 Current Sensor Comm TO" 21224 "BMS2 CellVoltageSamplingLinebrk" 21223 "BMS2 Cell Voltage Dropout Fault" 21222 "BMS2 Cell UnderVoltage Lvl3" 21221 "BMS2 Cell UnderVoltage Lvl2" 21220 "BMS2 Cell UnderVoltage Lvl1" 21219 "BMS2 Cell Temp Too Low Lvl3" 21218 "BMS2 Cell Temp Too Low Lvl2" 21217 "BMS2 Cell Temp Too Low Lvl1" 21216 "BMS2 Cell Temp TooHigh Lvl3" 21215 "BMS2 Cell Temp TooHigh Lvl2" 21214 "BMS2 Cell Temp TooHigh Lvl1" 21213 "BMS2 CellTempSamplingLineBreak" 21212 "BMS2 Cell Temp Diff Too High" 21211 "BMS2 Cell Over Voltage Lvl3" 21210 "BMS2 Cell Over Voltage Lvl2" 21209 "BMS2 Cell Over Voltage Lvl1" 21208 "BMS2 Cell Balancing Flt" 21207 "BMS2 Both Contactors Stuck" 21206 "BMS2 AFE Comm Lost" 21205 "VCU BMS2 Voltage high" 21204 "VCU BMS2 Voltage Low" 21203 "BMS2 Severe Fault" 21202 "BMS2 Fault" 21201 "BMS2 LOC" 21103 "BMS1 Server Fault" 21001 "StringsStateOfChargeUnbalanced" 21147 "BMS1 Batt Temp Rising TooQuickly" 21146 "BMS1 Serious Over Current" 21145 "BMS1 Precharge Relay Fault" 21144 "BMS1 Precharge Stuck Open Fault" 21143 "BMS1 Main Positive Relay Fault" 21142 "BMS1 Battery Under Voltage Lvl2" 21141 "BMS1 Battery Under Voltage Lvl1" 21140 "BMS1 Battery Over Voltage Lvl2" 21139 "BMS1 Battery Over Voltage Lvl1" 21138 "BMS1 Main Negative Relay Fault" 21137 "BMS1 Insulation Fault Lvl 3" 21136 "BMS1 Insulation Fault Lvl 2" 21135 "BMS1 Insulation Fault Lvl 1" 21134 "BMS1 HV Mode Comm Loss" 21133 "BMS1 HVIL Fault" 21132 "BMS1 Generated Curr TooHigh Lvl2" 21131 "BMS1 Generated Curr TooHigh Lvl1" 21130 "BMS1 Fuse Fault" 21129 "BMS1 Discharge Curr TooHigh Lvl2" 21128 "BMS1 Discharge Curr TooHigh Lvl1" 21127 "BMS1 CurrSnsr NoComm RelayStuck" 21126 "BMS1 Current Sensor Fault" 21125 "BMS1 Current Snsr Comm Timeout" 21124 "BMS1 Sampling Line Break" 21123 "BMS1 Cell Voltage Dropout " 21122 "BMS1 Cell UnderVoltage Lvl3" 21121 "BMS1 Cell UnderVoltage Lvl2" 21120 "BMS1 Cell UnderVoltage Lvl1" 21119 "BMS1 Cell Temp Too Low Lvl3" 21118 "BMS1 Cell Temp Too Low Lvl2" 21117 "BMS1 Cell Temp Too Low Lvl1" 21116 "BMS1 Cell Temp Too High Lvl3" 21115 "BMS1 Cell Temp Too High Lvl2" 21114 "BMS1 Cell Temp Too High Lvl1" 21113 "BMS1 Cell TempSamplingLineBreak" 21112 "BMS1 Cell Temp Diff Too High" 21111 "BMS1 Cell Over Volt Lvl3" 21110 "BMS1 Cell Over Volt Lvl2" 21109 "BMS1 Cell Over Volt Lvl1" 21108 "BMS1 Cell Balancing Flt" 21107 "BMS1 Both Contactors Stuck" 21106 "BMS1 AFE Comm Lost" 21105 "VCU BMS1 voltage high" 21104 "VCU BMS1 voltage low" 21102 "BMS1 Fault" 21101 "BMS1 LOC" 21000 "No Fault" 0 "No Fault" ;
VAL_ 1901 Hydraulic_Subsystem 20361 "Right Brake Link Limit Reached" 20360 "Left Brake Link Limit Reached" 20359 "Brakes stuck - shuttleshift stop" 20358 "Brake Pedal Pos OOR" 20357 "Drive clutch valve stuck open" 20356 "PTO clutch valve stuck open" 20355 "Right brake position sensor OC" 20354 "Left brake position sensor OC" 20353 "Work Pump Failed " 20300 "No Fault" 20352 "TractorPump LOC" 20351 "TractorPump Stalled" 20350 "TractorPump OverTemp" 20349 "TractorPump OverLoad" 20348 "TractorPump OverCurrent" 20347 "TractorPump OverVoltage" 20346 "TractorPump Hw Failure" 20345 "RH Brake Sensor Failure" 20344 "LH Brake Sensor Failure" 20343 "Work Pump Open Circuit" 20342 "4WD Bad Sensor" 20341 "Brakes Stuck - Speed Limit" 20340 "Brakes Stuck - RollBack" 20339 "Brakes Stuck - Parking" 20338 "Brakes Stuck - Pressure" 20337 "Work Pump Pos OOR" 20336 "Drive Clutch Pressure OOR" 20335 "PTO Clutch Pressure OOR" 20334 "Trans Acc Pressure OOR" 20333 "SteerBrk Acc Pressure OOR" 20332 "Suction Line Pressure OOR" 20331 "Tractor Pump Pressure OOR" 20330 "Work Pump Pressure OOR" 20329 "Right Brake Pressure OOR" 20328 "Left Brake Pressure OOR" 20327 "Tractor Pump Not Primed" 20326 "RH Brake Out Of Calibration" 20325 "LH Brake Out Of Calibration" 20324 "RH Brake SetValve OpenCircuit" 20323 "RH Brake RelValve OpenCircuit" 20322 "LH Brake SetValve OpenCircuit" 20321 "LH Brake RelValve OpenCircuit" 20320 "RH Brake Under Engagement" 20319 "LH Brake Under Engagement" 20318 "RH Brake Over Engagement" 20317 "LH Brake Over Engagement" 20316 "PTO Engagement Interlock" 20315 "PTO Clutch Valve OpenCircuit" 20314 "Lube Valve OpenCircuit" 20313 "Drive Clutch Valve OpenCircuit" 20312 "Lube Valve Timeout" 20311 "Hydraulic System Leak" 20310 "Clutch Pressure Low" 20309 "Aux ON/OFFvalve OpenCircuit" 20308 "WorkPumpOverloaded/Air" 20307 "WorkPumpSwash FBK Error" 20306 "TransFlowValve OpenCircuit" 20305 "Trans Manifold Pressure High" 20304 "Trans Manifold Pressure Low" 20303 "SteerBrake Valve OpenCircuit" 20302 "SteerBrake Acc Press High" 20301 "SteerBrake Acc Press Low" 0 "No Fault" ;
VAL_ 1901 Charging_Subsystem 20200 "No Fault" 20238 "ACDB eFuse OverCurrent" 20237 "ACDB outlet relay welded stuck" 20236 "ACDB SIMPL relay welded stuck" 20235 "ACDB EVSE relay welded stuck" 20234 "ACDB 3 Phase relay welded stuck" 20233 "ACDB 1 Phase relay welded stuck" 20232 "Chargers Disabled" 20231 "DCAC_3 Flt" 20230 "DCAC_2 Flt" 20229 "DCAC_1 Flt" 20228 "DCDC_3 Irregular Voltage" 20227 "DCDC_2 Irregular Voltage" 20226 "DCDC_1 Irregular Voltage" 20225 "Vmax3 OBC Flt" 20224 "Vmax2 OBC Flt" 20223 "Vmax1 OBC Flt" 20222 "DCDC_3 OverTemp" 20221 "DCDC_2 OverTemp" 20220 "DCDC_1 OverTemp" 20219 "Vmax3 OverTemp " 20218 "Vmax2 OverTemp" 20217 "Vmax1 OverTemp" 20216 "DCDC_3 Flt" 20215 "DCDC_2 Flt" 20214 "DCDC_1 Flt" 20213 "ACDB eFuse8 OverCurrent" 20212 "ACDB eFuse6 OverCurrent" 20211 "ACDB eFuse3 OverCurrent" 20210 "ACDB eFuse1 OverCurrent" 20209 "ACDB Conv. Error" 20208 "ACDB SIMPL Error" 20207 "ACDB EVSE Error" 20206 "ACDB 3Ph Error" 20205 "ACDB 1Ph Error" 20204 "ACDB OverTemp" 20203 "ACDB disabled" 20202 "Charger Improper Connection" 20201 "Charger LOC" 0 "No Fault" ;
VAL_ 1901 Thermal_Subsystem 20100 "No Fault" 20109 "Oil fans disabled" 20108 "Oil fan stopped/broken" 20107 "PE fans disabled" 20106 "PE fan stopped/broken" 20105 "Hyd Over Temp Protection" 20104 "Hyd Over Temp Warning" 20103 "Cooling Pump Disconnected" 20102 "Air in cooling system" 20101 "Cooling Pump OverCurrent" 0 "No Fault" ;
VAL_ 1901 Traction_Subsystem 20500 "No Fault" 20523 "Inverter LOC" 20522 "Regen Limited" 20521 "Regen Disabled" 20520 "Clutch Interlock" 20519 "Motor Over loaded" 20518 "bStart Check Fail" 20517 "Disengage by Accel." 20516 "Empty" 20515 "Empty" 20514 "Empty" 20513 "Speed Input Error" 20512 "Motor Torque Limit" 20511 "Insufficient Torque Applied" 20510 "Hydraulic Oil Over Temp" 20509 "Inverter Over Temperature" 20508 "Inverter Fault OFF" 20507 "Control Word Check Error" 20506 "Hand Throttle Error" 20505 "Hand Throttle Ch2 OOR" 20504 "Hand Throttle Ch1 OOR" 20503 "Foot Throttle Error" 20502 "Foot Throttle Ch2 OOR" 20501 "Foot Throttle Ch1 OOR" 0 "No Fault" ;
VAL_ 1300 ShiftFeedback 15 "Not in gear" 12 "HR" 11 "MR" 10 "LR" 9 "H3" 8 "H2" 7 "H1" 6 "M3" 5 "M2" 4 "M1" 3 "L3" 2 "L2" 1 "L1" 0 "N" ;
VAL_ 1300 Charger_PP 2 "Charger Connected" 1 "Charger Detected" 0 "Charger Not Connected" ;
VAL_ 1300 ShiftState 12 "Wait for clutch action" 11 "Rev match" 10 "FR shuttle-shift after regen" 9 "Regen to stop" 8 "Static gearshift abort" 7 "Rev match abort" 6 "Gear 1,3 shift 1" 5 "Gear 1,3 shift" 4 "Regular shift" 3 "Shift in motion" 2 "Stationary shift" 1 "Stationary" 0 "Undefined" ;
VAL_ 1585 FWD_Quadrant 5 "Locked4WD" 4 "Quadrant 4" 3 "Quadrant 3" 2 "Quadrant 2" 1 "Quadrant 1" 0 "2WD" ;
